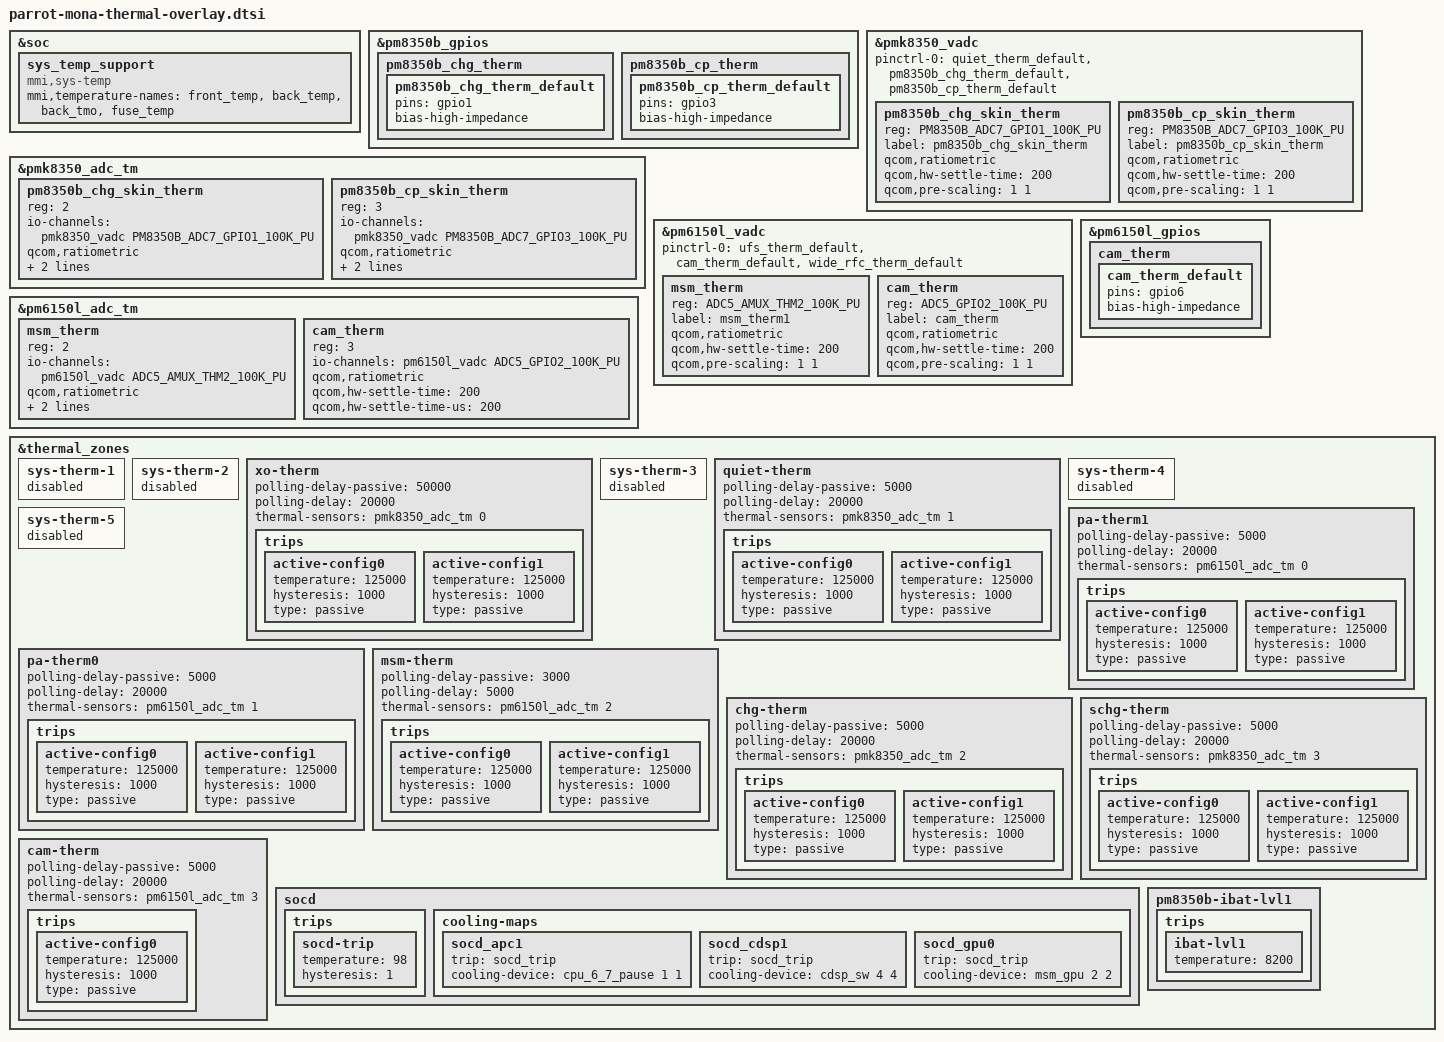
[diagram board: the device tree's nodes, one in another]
&soc {
	sys_temp_support {
		compatible = "mmi,sys-temp";
		mmi,temperature-names = "front_temp",
			"back_temp",
			"back_tmo",
			"fuse_temp";
		status = "ok";
	};
};

&pm8350b_gpios {
	pm8350b_chg_therm {
		pm8350b_chg_therm_default: pm8350b_chg_therm_default {
			pins = "gpio1";
			bias-high-impedance;
		};
	};

	pm8350b_cp_therm {
		pm8350b_cp_therm_default: pm8350b_cp_therm_default {
			pins = "gpio3";
			bias-high-impedance;
		};
	};
};

&pmk8350_vadc {
	pinctrl-names = "default";
	pinctrl-0 = <&quiet_therm_default &pm8350b_chg_therm_default &pm8350b_cp_therm_default>;

	pm8350b_chg_skin_therm {
		reg = <PM8350B_ADC7_GPIO1_100K_PU>;
		label = "pm8350b_chg_skin_therm";
		qcom,ratiometric;
		qcom,hw-settle-time = <200>;
		qcom,pre-scaling = <1 1>;
	};

	pm8350b_cp_skin_therm {
		reg = <PM8350B_ADC7_GPIO3_100K_PU>;
		label = "pm8350b_cp_skin_therm";
		qcom,ratiometric;
		qcom,hw-settle-time = <200>;
		qcom,pre-scaling = <1 1>;
	};
};

&pmk8350_adc_tm {
/*
	pmk8350_xo_therm {
		reg = <0>;
		io-channels = <&pmk8350_vadc PMK8350_ADC7_AMUX_THM1_100K_PU>;
		qcom,ratiometric;
		qcom,hw-settle-time = <200>;
		qcom,hw-settle-time-us = <200>;
	};

	pm6450_quiet_therm {
		reg = <1>;
		io-channels = <&pmk8350_vadc PM6450_ADC7_AMUX1_GPIO2_100K_PU>;
		qcom,ratiometric;
		qcom,hw-settle-time = <200>;
		qcom,hw-settle-time-us = <200>;
	};
*/
	pm8350b_chg_skin_therm {
		reg = <2>;
		io-channels = <&pmk8350_vadc PM8350B_ADC7_GPIO1_100K_PU>;
		qcom,ratiometric;
		qcom,hw-settle-time = <200>;
		qcom,hw-settle-time-us = <200>;
	};

	pm8350b_cp_skin_therm {
		reg = <3>;
		io-channels = <&pmk8350_vadc PM8350B_ADC7_GPIO3_100K_PU>;
		qcom,ratiometric;
		qcom,hw-settle-time = <200>;
		qcom,hw-settle-time-us = <200>;
	};
};

&pm6150l_vadc {
	pinctrl-0 = <&ufs_therm_default &cam_therm_default &wide_rfc_therm_default>;

	msm_therm {
		reg = <ADC5_AMUX_THM2_100K_PU>;
		label = "msm_therm1";
		qcom,ratiometric;
		qcom,hw-settle-time = <200>;
		qcom,pre-scaling = <1 1>;
	};
	cam_therm {
		reg = <ADC5_GPIO2_100K_PU>;
		label = "cam_therm";
		qcom,ratiometric;
		qcom,hw-settle-time = <200>;
		qcom,pre-scaling = <1 1>;
	};
};


&pm6150l_gpios {
	cam_therm {
		cam_therm_default: cam_therm_default {
			pins = "gpio6";
			bias-high-impedance;
		};
	};
};


&pm6150l_adc_tm {
/*
	pa_therm2 {
		reg = <0>;
		io-channels = <&pm6150l_vadc ADC5_AMUX_THM1_100K_PU>;
		qcom,ratiometric;
		qcom,hw-settle-time = <200>;
		qcom,hw-settle-time-us = <200>;
	};

	pa_therm1 {
		reg = <1>;
		io-channels = <&pm6150l_vadc ADC5_AMUX_THM3_100K_PU>;
		qcom,ratiometric;
		qcom,hw-settle-time = <200>;
		qcom,hw-settle-time-us = <200>;
	};

	ufs_therm {
		reg = <2>;
		io-channels = <&pm6150l_vadc ADC5_GPIO1_100K_PU>;
		qcom,ratiometric;
		qcom,hw-settle-time = <200>;
		qcom,hw-settle-time-us = <200>;
	};

	wide_rfc_therm {
		reg = <3>;
		io-channels = <&pm6150l_vadc ADC5_GPIO3_100K_PU>;
		qcom,ratiometric;
		qcom,hw-settle-time = <200>;
		qcom,hw-settle-time-us = <200>;
	};
*/
        /delete-node/ ufs_therm;
        /delete-node/ wide_rfc_therm;
	msm_therm {
		reg = <2>;
		io-channels = <&pm6150l_vadc ADC5_AMUX_THM2_100K_PU>;
		qcom,ratiometric;
		qcom,hw-settle-time = <200>;
		qcom,hw-settle-time-us = <200>;
	};

	cam_therm {
		reg = <3>;
		io-channels = <&pm6150l_vadc ADC5_GPIO2_100K_PU>;
		qcom,ratiometric;
		qcom,hw-settle-time = <200>;
		qcom,hw-settle-time-us = <200>;
	};
};

&thermal_zones {
	sys-therm-1 {
		status = "disabled";
	};
	sys-therm-2 {
		status = "disabled";
	};
	xo-therm {
		polling-delay-passive = <50000>;
		polling-delay = <20000>;
		thermal-sensors = <&pmk8350_adc_tm 0>;
		trips {
			active-config0 {
				temperature = <125000>;
				hysteresis = <1000>;
				type = "passive";
			};

			active-config1 {
				temperature = <125000>;
				hysteresis = <1000>;
				type = "passive";
			};
		};
	};


	sys-therm-3 {
		status = "disabled";
	};
	quiet-therm {
		polling-delay-passive = <5000>;
		polling-delay = <20000>;
		thermal-sensors = <&pmk8350_adc_tm 1 >; //PM6450_ADC7_AMUX1_GPIO2_100K_PU
		trips {
			active-config0 {
				temperature = <125000>;
				hysteresis = <1000>;
				type = "passive";
			};

			active-config1 {
				temperature = <125000>;
				hysteresis = <1000>;
				type = "passive";
			};
		};
	};

	sys-therm-4 {
		status = "disabled";
	};
	pa-therm1 {
		polling-delay-passive = <5000>;
		polling-delay = <20000>;
		thermal-sensors = <&pm6150l_adc_tm 0>; //ADC5_AMUX_THM1_100K_PU
		trips {
			active-config0 {
				temperature = <125000>;
				hysteresis = <1000>;
				type = "passive";
			};

			active-config1 {
				temperature = <125000>;
				hysteresis = <1000>;
				type = "passive";
			};
		};
	};
	sys-therm-5 {
		status = "disabled";
	};
	pa-therm0 {
		polling-delay-passive = <5000>;
		polling-delay = <20000>;
		thermal-sensors = <&pm6150l_adc_tm 1>; //ADC5_AMUX_THM3_100K_PU
		trips {
			active-config0 {
				temperature = <125000>;
				hysteresis = <1000>;
				type = "passive";
			};

			active-config1 {
				temperature = <125000>;
				hysteresis = <1000>;
				type = "passive";
			};
		};
	};

	msm-therm {
		polling-delay-passive = <3000>;
		polling-delay = <5000>;
		thermal-sensors = <&pm6150l_adc_tm 2>;
		trips {
			active-config0 {
				temperature = <125000>;
				hysteresis = <1000>;
				type = "passive";
			};

			active-config1 {
				temperature = <125000>;
				hysteresis = <1000>;
				type = "passive";
			};
		};
	};


	chg-therm {
		polling-delay-passive = <5000>;
		polling-delay = <20000>;
		thermal-sensors = <&pmk8350_adc_tm 2>; //PM8350B_ADC7_GPIO1_100K_PU
		trips {
			active-config0 {
				temperature = <125000>;
				hysteresis = <1000>;
				type = "passive";
			};

			active-config1 {
				temperature = <125000>;
				hysteresis = <1000>;
				type = "passive";
			};
		};
	};

	schg-therm {
		polling-delay-passive = <5000>;
		polling-delay = <20000>;
		thermal-sensors = <&pmk8350_adc_tm 3>; //PM8350B_ADC7_GPIO3_100K_PU
		trips {
			active-config0 {
				temperature = <125000>;
				hysteresis = <1000>;
				type = "passive";
			};

			active-config1 {
				temperature = <125000>;
				hysteresis = <1000>;
				type = "passive";
			};
		};
	};

	cam-therm {
		polling-delay-passive = <5000>;
		polling-delay = <20000>;
		thermal-sensors = <&pm6150l_adc_tm 3>;
		trips {
			active-config0 {
				temperature = <125000>;
				hysteresis = <1000>;
				type = "passive";
			};
		};
	};

    socd {
		trips {
			socd-trip {
				temperature = <98>;
				hysteresis = <1>;
			};
		};

		cooling-maps {
			socd_apc1 {
				trip = <&socd_trip>;
				cooling-device = <&cpu_6_7_pause 1 1>;
			};

			socd_cdsp1 {
				trip = <&socd_trip>;
				cooling-device = <&cdsp_sw 4 4>;
			};

			socd_gpu0 {
				trip = <&socd_trip>;
				cooling-device = <&msm_gpu 2 2>;
			};
		};
	};

    pm8350b-ibat-lvl1 {
		trips {
			ibat-lvl1 {
				temperature = <8200>;
			};
		};
	};

};

